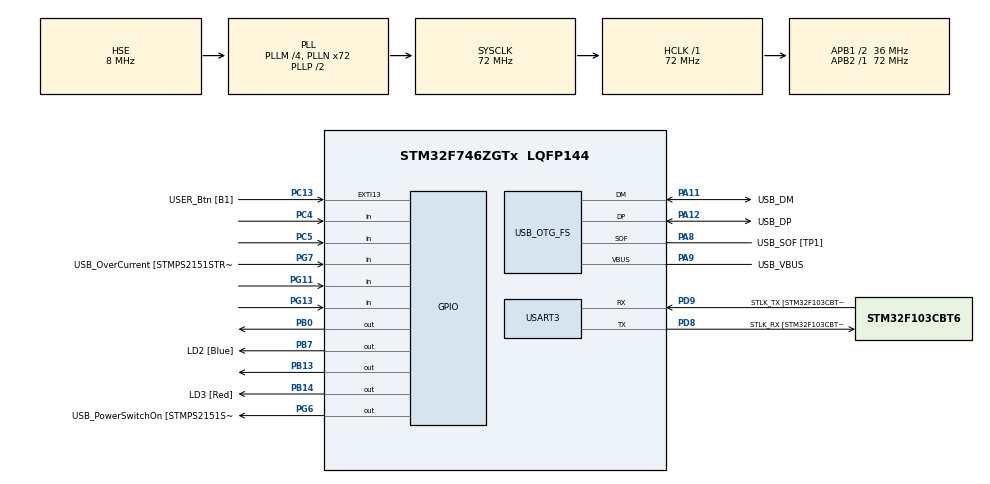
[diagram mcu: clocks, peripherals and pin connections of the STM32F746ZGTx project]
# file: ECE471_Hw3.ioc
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Mcu.Family=STM32F7
Mcu.Name=STM32F746ZGTx
Mcu.Package=LQFP144
NVIC.EXTI15_10_IRQn=true\:0\:0\:false\:false\:true\:true\:true\:true
NVIC.PriorityGroup=NVIC_PRIORITYGROUP_4
NVIC.TIM2_IRQn=true\:0\:0\:false\:false\:true\:true\:true\:true
PA1.GPIO_Label=RMII_REF_CLK [LAN8742A-CZ-TR_REFCLK0]
PA1.Signal=ETH_REF_CLK
PA10.GPIO_Label=USB_ID
PA10.Signal=USB_OTG_FS_ID
PA11.GPIO_Label=USB_DM
PA11.Mode=Device_Only
PA11.Signal=USB_OTG_FS_DM
PA12.GPIO_Label=USB_DP
PA12.Mode=Device_Only
PA12.Signal=USB_OTG_FS_DP
PA13.GPIO_Label=TMS
PA13.Mode=Serial_Wire
PA13.Signal=SYS_JTMS-SWDIO
PA14.GPIO_Label=TCK
PA14.Mode=Serial_Wire
PA14.Signal=SYS_JTCK-SWCLK
PA2.GPIO_Label=RMII_MDIO [LAN8742A-CZ-TR_MDIO]
PA2.Signal=ETH_MDIO
PA8.GPIO_Label=USB_SOF [TP1]
PA8.Mode=Activate_SOF_FS
PA8.Signal=USB_OTG_FS_SOF
PA9.GPIO_Label=USB_VBUS
PA9.Mode=Activate_VBUS
PA9.Signal=USB_OTG_FS_VBUS
PB0.Signal=GPIO_Output
PB13.Signal=GPIO_Output
PB14.GPIO_Label=LD3 [Red]
PB14.Signal=GPIO_Output
PB3.GPIO_Label=SW0
PB3.Signal=SYS_JTDO-SWO
PB7.GPIO_Label=LD2 [Blue]
PB7.Signal=GPIO_Output
PC1.GPIO_Label=RMII_MDC [LAN8742A-CZ-TR_MDC]
PC1.Signal=ETH_MDC
PC13.GPIO_Label=USER_Btn [B1]
PC13.Signal=GPXTI13
PC14/OSC32_IN.Mode=LSE-External-Oscillator
PC14/OSC32_IN.Signal=RCC_OSC32_IN
PC15/OSC32_OUT.Mode=LSE-External-Oscillator
PC15/OSC32_OUT.Signal=RCC_OSC32_OUT
PC4.Signal=GPIO_Input
PC5.Signal=GPIO_Input
PD8.GPIO_Label=STLK_RX [STM32F103CBT6_PA3]
PD8.GPIO_PuPd=GPIO_PULLUP
PD8.Mode=Asynchronous
PD8.Signal=USART3_TX
PD9.GPIO_Label=STLK_TX [STM32F103CBT6_PA2]
PD9.GPIO_PuPd=GPIO_PULLUP
PD9.Mode=Asynchronous
PD9.Signal=USART3_RX
PG11.Signal=GPIO_Input
PG13.Signal=GPIO_Input
PG6.GPIO_Label=USB_PowerSwitchOn [STMPS2151STR_EN]
PG6.Signal=GPIO_Output
PG7.GPIO_Label=USB_OverCurrent [STMPS2151STR_FAULT]
PG7.Signal=GPIO_Input
PH0/OSC_IN.GPIO_Label=MCO [STM32F103CBT6_PA8]
PH0/OSC_IN.Mode=HSE-External-Clock-Source
PH0/OSC_IN.Signal=RCC_OSC_IN
PH1/OSC_OUT.Mode=HSE-External-Clock-Source
PH1/OSC_OUT.Signal=RCC_OSC_OUT
ProjectManager.HeapSize=0x200
ProjectManager.StackSize=0x400
ProjectManager.TargetToolchain=STM32CubeIDE
RCC.48MHZClocksFreq_Value=24000000
RCC.AHBFreq_Value=72000000
RCC.APB1CLKDivider=RCC_HCLK_DIV2
RCC.APB1Freq_Value=36000000
RCC.APB1TimFreq_Value=72000000
RCC.APB2Freq_Value=72000000
RCC.APB2TimFreq_Value=72000000
RCC.CortexFreq_Value=72000000
RCC.HCLKFreq_Value=72000000
RCC.HSE_VALUE=8000000
RCC.HSI_VALUE=16000000
RCC.PLLM=4
RCC.PLLMUL=RCC_PLL_MUL9
RCC.PLLN=72
RCC.PLLQ=3
RCC.PRESCALERUSB=RCC_USBCLKSOURCE_PLL_DIV1_5
RCC.SYSCLKFreq_VALUE=72000000
RCC.SYSCLKSource=RCC_SYSCLKSOURCE_PLLCLK
RCC.SYSCLKSourceVirtual=RCC_SYSCLKSOURCE_PLLCLK
RCC.USBFreq_Value=48000000
RCC.VCOOutputFreq_Value=144000000
TIM2.Channel-PWM\ Generation2\ No\ Output=TIM_CHANNEL_2
TIM2.Period=999999
TIM2.Prescaler=71
USART3.VirtualMode-Asynchronous=VM_ASYNC
USB_OTG_FS.VirtualMode=Device_Only
VP_TIM2_VS_ClockSourceINT.Mode=Internal
VP_TIM2_VS_ClockSourceITR.Mode=TriggerSource_ITR2
VP_TIM2_VS_no_output2.Mode=PWM Generation2 No Output
board=NUCLEO-F746ZG

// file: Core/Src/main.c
/* USER CODE BEGIN Header */
/**
  ******************************************************************************
  * @file           : main.c
  * @brief          : Main program body
  ******************************************************************************
  * @attention
  *
  * Copyright (c) 2023 STMicroelectronics.
  * All rights reserved.
  *
  * This software is licensed under terms that can be found in the LICENSE file
  * in the root directory of this software component.
  * If no LICENSE file comes with this software, it is provided AS-IS.
  *
  ******************************************************************************
  */
/* USER CODE END Header */
#include "main.h"

TIM_HandleTypeDef htim2;

UART_HandleTypeDef huart3;

PCD_HandleTypeDef hpcd_USB_OTG_FS;

void SystemClock_Config(void);
static void MX_GPIO_Init(void);
static void MX_USART3_UART_Init(void);
static void MX_USB_OTG_FS_PCD_Init(void);
static void MX_TIM2_Init(void);
/* USER CODE BEGIN PFP */
enum status {
	  unexpired,
	  expired
  };

void quickBlink(enum status status);
void slowBlink(enum status status);
/* USER CODE END PFP */

void quickBlink(enum status status){
	if (status == unexpired){	//unexpired
		HAL_GPIO_WritePin(GPIOB, GPIO_PIN_0, GPIO_PIN_SET); //green
		HAL_Delay(100);
		HAL_GPIO_WritePin(GPIOB, GPIO_PIN_0, GPIO_PIN_RESET); //green
		HAL_Delay(100);
	}
	else{	//expired
		HAL_GPIO_WritePin(GPIOB, GPIO_PIN_14, GPIO_PIN_SET); //red
		HAL_Delay(100);
		HAL_GPIO_WritePin(GPIOB, GPIO_PIN_14, GPIO_PIN_RESET); //red
		HAL_Delay(100);
	}
}

void slowBlink(enum status status){
	if (status == unexpired){	//unexpired
			HAL_GPIO_WritePin(GPIOB, GPIO_PIN_0, GPIO_PIN_SET); //green
			HAL_Delay(250);
			HAL_GPIO_WritePin(GPIOB, GPIO_PIN_0, GPIO_PIN_RESET); //green
			HAL_Delay(250);
		}
		else{	//expired
			HAL_GPIO_WritePin(GPIOB, GPIO_PIN_14, GPIO_PIN_SET); //red
			HAL_Delay(250);
			HAL_GPIO_WritePin(GPIOB, GPIO_PIN_14, GPIO_PIN_RESET); //red
			HAL_Delay(250);
		}
}

static int loopCount =0;
static enum status status= unexpired;
#define LONG_PRESS_THRESHOLD 3

int main(void)
{

  HAL_Init();
  SystemClock_Config();
  MX_GPIO_Init();
  MX_USART3_UART_Init();
  MX_USB_OTG_FS_PCD_Init();
  MX_TIM2_Init();
  /* USER CODE BEGIN 2 */
  HAL_TIM_Base_Init(&htim2);
  HAL_TIM_Base_Start_IT(&htim2);
  HAL_NVIC_SetPriority(TIM2_IRQn, 0, 0);
  HAL_NVIC_EnableIRQ(TIM2_IRQn);

  /* USER CODE END 2 */

      	  int buttonPressed = 0;
          int pressDuration = 0;
          int filterCount =0;

          while (1)
              {
                  HAL_SuspendTick();
                  HAL_PWR_EnterSLEEPMode(PWR_LOWPOWERREGULATOR_ON, PWR_SLEEPENTRY_WFI);
                  HAL_ResumeTick();

                  GPIO_PinState buttonState = HAL_GPIO_ReadPin(GPIOC, GPIO_PIN_13);

                  if (btnFlag == 1)
                  {
                      if (buttonState == GPIO_PIN_SET)
                      {
                          if (!buttonPressed)
                          {
                              buttonPressed = 1;
                              pressDuration = 0;
                          }

                          // Increment the pressDuration while the button is pressed
                          pressDuration++;

                          // Check for a long press
                          if (pressDuration >= LONG_PRESS_THRESHOLD)
                          {
                        	  status=unexpired;
                              for (int i = 0; i < 5; i++)
                              {
                                  slowBlink(status);
                              }

                              // Reset pressDuration to allow for short presses
                              pressDuration = 0;
                          }
                      }
                      else
                      {
                          // Button is released
                          buttonPressed = 0;

                          // Check for a short press
                          if (pressDuration < LONG_PRESS_THRESHOLD && pressDuration > 0)
                          {
                        	  filterCount++;
                              for (int i = 0; i < 5; i++)
                              {
                                  quickBlink(status);
                              }
                          }

                          // Reset pressDuration when the button is released
                          pressDuration = 0;
                      }
                  }
                  if(filterCount==10 || btnTimer>=180){	//20 seconds for demo purposes
                	  status = expired;
                	  filterCount=0;
                  }

              }
}

void SystemClock_Config(void)
{
  RCC_OscInitTypeDef RCC_OscInitStruct = {0};
  RCC_ClkInitTypeDef RCC_ClkInitStruct = {0};

  /** Configure LSE Drive Capability
  */
  HAL_PWR_EnableBkUpAccess();

  /** Configure the main internal regulator output voltage
  */
  __HAL_RCC_PWR_CLK_ENABLE();
  __HAL_PWR_VOLTAGESCALING_CONFIG(PWR_REGULATOR_VOLTAGE_SCALE3);

  /** Initializes the RCC Oscillators according to the specified parameters
  * in the RCC_OscInitTypeDef structure.
  */
  RCC_OscInitStruct.OscillatorType = RCC_OSCILLATORTYPE_HSE;
  RCC_OscInitStruct.HSEState = RCC_HSE_BYPASS;
  RCC_OscInitStruct.PLL.PLLState = RCC_PLL_ON;
  RCC_OscInitStruct.PLL.PLLSource = RCC_PLLSOURCE_HSE;
  RCC_OscInitStruct.PLL.PLLM = 4;
  RCC_OscInitStruct.PLL.PLLN = 72;
  RCC_OscInitStruct.PLL.PLLP = RCC_PLLP_DIV2;
  RCC_OscInitStruct.PLL.PLLQ = 3;
  if (HAL_RCC_OscConfig(&RCC_OscInitStruct) != HAL_OK)
  {
    Error_Handler();
  }

  /** Initializes the CPU, AHB and APB buses clocks
  */
  RCC_ClkInitStruct.ClockType = RCC_CLOCKTYPE_HCLK|RCC_CLOCKTYPE_SYSCLK
                              |RCC_CLOCKTYPE_PCLK1|RCC_CLOCKTYPE_PCLK2;
  RCC_ClkInitStruct.SYSCLKSource = RCC_SYSCLKSOURCE_PLLCLK;
  RCC_ClkInitStruct.AHBCLKDivider = RCC_SYSCLK_DIV1;
  RCC_ClkInitStruct.APB1CLKDivider = RCC_HCLK_DIV2;
  RCC_ClkInitStruct.APB2CLKDivider = RCC_HCLK_DIV1;

  if (HAL_RCC_ClockConfig(&RCC_ClkInitStruct, FLASH_LATENCY_2) != HAL_OK)
  {
    Error_Handler();
  }
}

static void MX_TIM2_Init(void)
{

  TIM_ClockConfigTypeDef sClockSourceConfig = {0};
  TIM_SlaveConfigTypeDef sSlaveConfig = {0};
  TIM_MasterConfigTypeDef sMasterConfig = {0};
  TIM_OC_InitTypeDef sConfigOC = {0};

  htim2.Instance = TIM2;
  htim2.Init.Prescaler = 71;
  htim2.Init.CounterMode = TIM_COUNTERMODE_UP;
  htim2.Init.Period = 999999;
  htim2.Init.ClockDivision = TIM_CLOCKDIVISION_DIV1;
  htim2.Init.AutoReloadPreload = TIM_AUTORELOAD_PRELOAD_DISABLE;
  if (HAL_TIM_Base_Init(&htim2) != HAL_OK)
  {
    Error_Handler();
  }
  sClockSourceConfig.ClockSource = TIM_CLOCKSOURCE_INTERNAL;
  if (HAL_TIM_ConfigClockSource(&htim2, &sClockSourceConfig) != HAL_OK)
  {
    Error_Handler();
  }
  if (HAL_TIM_PWM_Init(&htim2) != HAL_OK)
  {
    Error_Handler();
  }
  sSlaveConfig.SlaveMode = TIM_SLAVEMODE_DISABLE;
  sSlaveConfig.InputTrigger = TIM_TS_ITR2;
  if (HAL_TIM_SlaveConfigSynchro(&htim2, &sSlaveConfig) != HAL_OK)
  {
    Error_Handler();
  }
  sMasterConfig.MasterOutputTrigger = TIM_TRGO_RESET;
  sMasterConfig.MasterSlaveMode = TIM_MASTERSLAVEMODE_DISABLE;
  if (HAL_TIMEx_MasterConfigSynchronization(&htim2, &sMasterConfig) != HAL_OK)
  {
    Error_Handler();
  }
  sConfigOC.OCMode = TIM_OCMODE_PWM1;
  sConfigOC.Pulse = 0;
  sConfigOC.OCPolarity = TIM_OCPOLARITY_HIGH;
  sConfigOC.OCFastMode = TIM_OCFAST_DISABLE;
  if (HAL_TIM_PWM_ConfigChannel(&htim2, &sConfigOC, TIM_CHANNEL_2) != HAL_OK)
  {
    Error_Handler();
  }

}

static void MX_USART3_UART_Init(void)
{

  huart3.Instance = USART3;
  huart3.Init.BaudRate = 115200;
  huart3.Init.WordLength = UART_WORDLENGTH_8B;
  huart3.Init.StopBits = UART_STOPBITS_1;
  huart3.Init.Parity = UART_PARITY_NONE;
  huart3.Init.Mode = UART_MODE_TX_RX;
  huart3.Init.HwFlowCtl = UART_HWCONTROL_NONE;
  huart3.Init.OverSampling = UART_OVERSAMPLING_16;
  huart3.Init.OneBitSampling = UART_ONE_BIT_SAMPLE_DISABLE;
  huart3.AdvancedInit.AdvFeatureInit = UART_ADVFEATURE_NO_INIT;
  if (HAL_UART_Init(&huart3) != HAL_OK)
  {
    Error_Handler();
  }

}

static void MX_USB_OTG_FS_PCD_Init(void)
{

  hpcd_USB_OTG_FS.Instance = USB_OTG_FS;
  hpcd_USB_OTG_FS.Init.dev_endpoints = 6;
  hpcd_USB_OTG_FS.Init.speed = PCD_SPEED_FULL;
  hpcd_USB_OTG_FS.Init.dma_enable = DISABLE;
  hpcd_USB_OTG_FS.Init.phy_itface = PCD_PHY_EMBEDDED;
  hpcd_USB_OTG_FS.Init.Sof_enable = ENABLE;
  hpcd_USB_OTG_FS.Init.low_power_enable = DISABLE;
  hpcd_USB_OTG_FS.Init.lpm_enable = DISABLE;
  hpcd_USB_OTG_FS.Init.vbus_sensing_enable = ENABLE;
  hpcd_USB_OTG_FS.Init.use_dedicated_ep1 = DISABLE;
  if (HAL_PCD_Init(&hpcd_USB_OTG_FS) != HAL_OK)
  {
    Error_Handler();
  }

}

static void MX_GPIO_Init(void)
{
  GPIO_InitTypeDef GPIO_InitStruct = {0};

  /* GPIO Ports Clock Enable */
  __HAL_RCC_GPIOC_CLK_ENABLE();
  __HAL_RCC_GPIOH_CLK_ENABLE();
  __HAL_RCC_GPIOA_CLK_ENABLE();
  __HAL_RCC_GPIOB_CLK_ENABLE();
  __HAL_RCC_GPIOD_CLK_ENABLE();
  __HAL_RCC_GPIOG_CLK_ENABLE();

  /*Configure GPIO pin Output Level */
  HAL_GPIO_WritePin(GPIOB, GPIO_PIN_0|GPIO_PIN_13|LD3_Pin|LD2_Pin, GPIO_PIN_RESET);

  /*Configure GPIO pin Output Level */
  HAL_GPIO_WritePin(USB_PowerSwitchOn_GPIO_Port, USB_PowerSwitchOn_Pin, GPIO_PIN_RESET);

  /*Configure GPIO pin : USER_Btn_Pin */
  GPIO_InitStruct.Pin = USER_Btn_Pin;
  GPIO_InitStruct.Mode = GPIO_MODE_IT_RISING;
  GPIO_InitStruct.Pull = GPIO_NOPULL;
  HAL_GPIO_Init(USER_Btn_GPIO_Port, &GPIO_InitStruct);

  /*Configure GPIO pin : RMII_MDC_Pin */
  GPIO_InitStruct.Pin = RMII_MDC_Pin;
  GPIO_InitStruct.Mode = GPIO_MODE_AF_PP;
  GPIO_InitStruct.Pull = GPIO_NOPULL;
  GPIO_InitStruct.Speed = GPIO_SPEED_FREQ_VERY_HIGH;
  GPIO_InitStruct.Alternate = GPIO_AF11_ETH;
  HAL_GPIO_Init(RMII_MDC_GPIO_Port, &GPIO_InitStruct);

  /*Configure GPIO pins : RMII_REF_CLK_Pin RMII_MDIO_Pin */
  GPIO_InitStruct.Pin = RMII_REF_CLK_Pin|RMII_MDIO_Pin;
  GPIO_InitStruct.Mode = GPIO_MODE_AF_PP;
  GPIO_InitStruct.Pull = GPIO_NOPULL;
  GPIO_InitStruct.Speed = GPIO_SPEED_FREQ_VERY_HIGH;
  GPIO_InitStruct.Alternate = GPIO_AF11_ETH;
  HAL_GPIO_Init(GPIOA, &GPIO_InitStruct);

  /*Configure GPIO pins : PC4 PC5 */
  GPIO_InitStruct.Pin = GPIO_PIN_4|GPIO_PIN_5;
  GPIO_InitStruct.Mode = GPIO_MODE_INPUT;
  GPIO_InitStruct.Pull = GPIO_NOPULL;
  HAL_GPIO_Init(GPIOC, &GPIO_InitStruct);

  /*Configure GPIO pins : PB0 PB13 LD3_Pin LD2_Pin */
  GPIO_InitStruct.Pin = GPIO_PIN_0|GPIO_PIN_13|LD3_Pin|LD2_Pin;
  GPIO_InitStruct.Mode = GPIO_MODE_OUTPUT_PP;
  GPIO_InitStruct.Pull = GPIO_NOPULL;
  GPIO_InitStruct.Speed = GPIO_SPEED_FREQ_LOW;
  HAL_GPIO_Init(GPIOB, &GPIO_InitStruct);

  /*Configure GPIO pin : USB_PowerSwitchOn_Pin */
  GPIO_InitStruct.Pin = USB_PowerSwitchOn_Pin;
  GPIO_InitStruct.Mode = GPIO_MODE_OUTPUT_PP;
  GPIO_InitStruct.Pull = GPIO_NOPULL;
  GPIO_InitStruct.Speed = GPIO_SPEED_FREQ_LOW;
  HAL_GPIO_Init(USB_PowerSwitchOn_GPIO_Port, &GPIO_InitStruct);

  /*Configure GPIO pins : USB_OverCurrent_Pin PG11 PG13 */
  GPIO_InitStruct.Pin = USB_OverCurrent_Pin|GPIO_PIN_11|GPIO_PIN_13;
  GPIO_InitStruct.Mode = GPIO_MODE_INPUT;
  GPIO_InitStruct.Pull = GPIO_NOPULL;
  HAL_GPIO_Init(GPIOG, &GPIO_InitStruct);

  /* EXTI interrupt init*/
  HAL_NVIC_SetPriority(EXTI15_10_IRQn, 0, 0);
  HAL_NVIC_EnableIRQ(EXTI15_10_IRQn);

}

void Error_Handler(void)
{
  __disable_irq();
  while (1)
  {
  }
}
